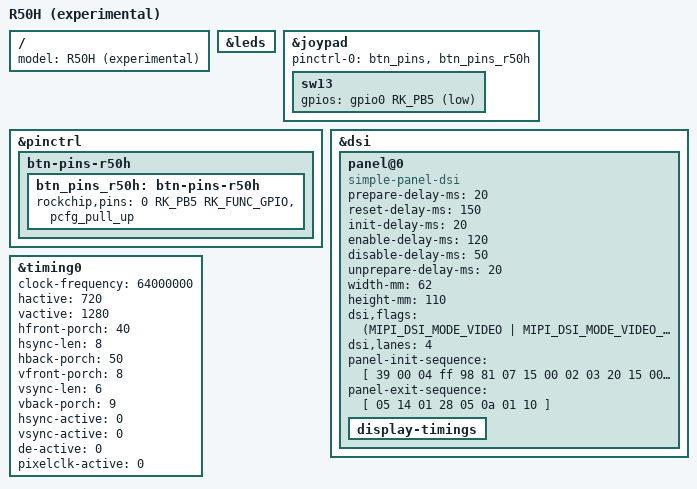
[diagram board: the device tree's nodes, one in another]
// SPDX-License-Identifier: (GPL-2.0+ OR MIT)
/*
 * EXPERIMENTAL - not tested on hardware by andr36oid. Keep a copy of the
 * files you replace so you can go back.
 *
 * HL-R50H-V11 (R50H): the R46H board with a 720x1280 panel mounted
 * sideways. Against rk3326-r46h-android.dts: other panel, Fn button on
 * GPIO0_B5 (R46H: GPIO2_A4), so no charge LED on that pin.
 * The same DTB is in arkos4clone as "r50h" (same init sequence).
 * Boot with androidboot.sf_orientation=ORIENTATION_270 fbcon=rotate:3
 * (stock boot.ini has fbcon=rotate:3 and the panel node rotation = 90).
 *
 * Panel values (delays, size, flags, init and exit sequence, timing) are
 * copied from the reference DTB:
 *   djparentx/dArkOSen-R36S @28f5427f, boot/dtb/r36s/HL-R50H-V11 2026-03-31 2617
 *   init sequence 816 bytes, md5 ce000ad21b3f
 */

/dts-v1/;

#include "rk3326-r46h-android.dts"

/ {
	model = "R50H (experimental)";
};

&leds {
	/* GPIO0_B5 is the Fn button on this board */
	/delete-node/ charge;
};

&joypad {
	/delete-property/ andr36oid,missing-buttons;
	/delete-property/ switch-rxy;
	/delete-property/ invert-absry;

	sw13 {
		gpios = <&gpio0 RK_PB5 GPIO_ACTIVE_LOW>;
	};
};

&pinctrl {
	btn-pins-r50h {
		btn_pins_r50h: btn-pins-r50h {
			rockchip,pins = <0 RK_PB5 RK_FUNC_GPIO &pcfg_pull_up>;
		};
	};
};

&joypad {
	pinctrl-0 = <&btn_pins &btn_pins_r50h>;
};

&dsi {
	panel@0 {
		compatible = "simple-panel-dsi";
		prepare-delay-ms = <20>;
		reset-delay-ms = <150>;
		init-delay-ms = <20>;
		enable-delay-ms = <120>;
		disable-delay-ms = <50>;
		unprepare-delay-ms = <20>;
		width-mm = <62>;
		height-mm = <110>;
		dsi,flags = <(MIPI_DSI_MODE_VIDEO |
		      MIPI_DSI_MODE_VIDEO_BURST |
		      MIPI_DSI_MODE_EOT_PACKET |
		      MIPI_DSI_MODE_LPM)>;
		dsi,lanes = <4>;
		panel-init-sequence = [
			39 00 04 ff 98 81 07
			15 00 02 03 20
			15 00 02 04 06
			15 00 02 05 00
			15 00 02 06 01
			15 00 02 07 00
			15 00 02 08 00
			15 00 02 09 00
			15 00 02 0a 00
			15 00 02 0b 2f
			15 00 02 0c 00
			15 00 02 0d 00
			15 00 02 0e 00
			15 00 02 0f 00
			15 00 02 10 40
			15 00 02 11 02
			15 00 02 12 05
			15 00 02 13 00
			15 00 02 14 00
			15 00 02 15 00
			15 00 02 16 2f
			15 00 02 17 2f
			15 00 02 18 00
			15 00 02 19 00
			15 00 02 1a 00
			15 00 02 1b 50
			15 00 02 1c bc
			15 00 02 1d 0c
			15 00 02 1e 00
			15 00 02 1f 00
			15 00 02 20 00
			15 00 02 21 00
			15 00 02 22 00
			15 00 02 23 c0
			15 00 02 24 30
			15 00 02 25 00
			15 00 02 26 00
			15 00 02 27 03
			15 00 02 30 01
			15 00 02 31 23
			15 00 02 32 45
			15 00 02 33 67
			15 00 02 34 89
			15 00 02 35 ab
			15 00 02 36 01
			15 00 02 37 23
			15 00 02 38 45
			15 00 02 39 67
			15 00 02 3a 89
			15 00 02 3b ab
			15 00 02 3c cd
			15 00 02 3d ef
			15 00 02 50 11
			15 00 02 51 06
			15 00 02 52 0c
			15 00 02 53 0d
			15 00 02 54 0e
			15 00 02 55 0f
			15 00 02 56 02
			15 00 02 57 02
			15 00 02 58 02
			15 00 02 59 02
			15 00 02 5a 02
			15 00 02 5b 02
			15 00 02 5c 02
			15 00 02 5d 02
			15 00 02 5e 02
			15 00 02 5f 02
			15 00 02 60 05
			15 00 02 61 05
			15 00 02 62 05
			15 00 02 63 02
			15 00 02 64 01
			15 00 02 65 00
			15 00 02 66 08
			15 00 02 67 08
			15 00 02 68 0c
			15 00 02 69 0d
			15 00 02 6a 0e
			15 00 02 6b 0f
			15 00 02 6c 02
			15 00 02 6d 02
			15 00 02 6e 02
			15 00 02 6f 02
			15 00 02 70 02
			15 00 02 71 02
			15 00 02 72 02
			15 00 02 73 02
			15 00 02 74 02
			15 00 02 75 02
			15 00 02 76 05
			15 00 02 77 05
			15 00 02 78 05
			15 00 02 79 02
			15 00 02 7a 01
			15 00 02 7b 00
			15 00 02 7c 06
			39 00 04 ff 98 81 08
			15 00 02 76 b4
			15 00 02 78 02
			15 00 02 74 2b
			15 00 02 8e 15
			15 00 02 40 01
			15 00 02 84 81
			15 00 02 72 25
			15 00 02 e3 75
			15 00 02 7d cb
			15 00 02 7e 49
			15 00 02 49 10
			15 00 02 32 05
			15 00 02 3c 05
			39 00 04 ff 98 81 01
			15 00 02 22 0a
			15 00 02 43 01
			15 00 02 53 82
			15 00 02 55 85
			15 00 02 50 b9
			15 00 02 51 ba
			15 00 02 31 00
			15 00 02 a0 00
			15 00 02 a1 14
			15 00 02 a2 2b
			15 00 02 a3 16
			15 00 02 a4 1c
			15 00 02 a5 2e
			15 00 02 a6 18
			15 00 02 a7 20
			15 00 02 a8 78
			15 00 02 a9 20
			15 00 02 aa 2a
			15 00 02 ab 83
			15 00 02 ac 25
			15 00 02 ad 1b
			15 00 02 ae 54
			15 00 02 af 2b
			15 00 02 b0 2b
			15 00 02 b1 4f
			15 00 02 b2 67
			15 00 02 b3 39
			15 00 02 c0 00
			15 00 02 c1 14
			15 00 02 c2 2b
			15 00 02 c3 16
			15 00 02 c4 1c
			15 00 02 c5 2e
			15 00 02 c6 18
			15 00 02 c7 20
			15 00 02 c8 78
			15 00 02 c9 20
			15 00 02 ca 2a
			15 00 02 cb 83
			15 00 02 cc 25
			15 00 02 cd 1b
			15 00 02 ce 54
			15 00 02 cf 2b
			15 00 02 d0 2b
			15 00 02 d1 4f
			15 00 02 d2 67
			15 00 02 d3 39
			39 00 04 ff 98 81 00
			05 78 01 11
			05 14 01 29
		];
		panel-exit-sequence = [
			05 14 01 28
			05 0a 01 10
		];
		display-timings {
			/* one mode only: the R36S alternates do not fit this panel */
			/delete-node/ timing1;
			/delete-node/ timing2;
		};
	};
};

&timing0 {
	clock-frequency = <64000000>;
	hactive = <720>;
	vactive = <1280>;
	hfront-porch = <40>;
	hsync-len = <8>;
	hback-porch = <50>;
	vfront-porch = <8>;	/* stock value, 60.05 Hz */
	vsync-len = <6>;
	vback-porch = <9>;
	hsync-active = <0>;
	vsync-active = <0>;
	de-active = <0>;
	pixelclk-active = <0>;
};
